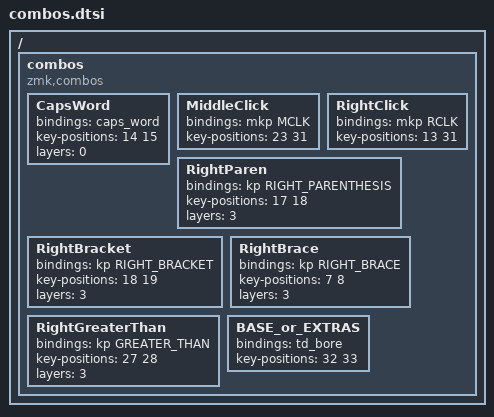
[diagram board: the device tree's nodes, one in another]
/ {
    combos {
        compatible = "zmk,combos";

        CapsWord {
            bindings = <&caps_word>;
            key-positions = <14 15>;
            layers = <0>;
        };

        MiddleClick {
            bindings = <&mkp MCLK>;
            key-positions = <23 31>;
        };

        RightClick {
            bindings = <&mkp RCLK>;
            key-positions = <13 31>;
        };

        RightParen {
            bindings = <&kp RIGHT_PARENTHESIS>;
            key-positions = <17 18>;
            layers = <3>;
        };

        RightBracket {
            bindings = <&kp RIGHT_BRACKET>;
            key-positions = <18 19>;
            layers = <3>;
        };

        RightBrace {
            bindings = <&kp RIGHT_BRACE>;
            key-positions = <7 8>;
            layers = <3>;
        };

        RightGreaterThan {
            bindings = <&kp GREATER_THAN>;
            key-positions = <27 28>;
            layers = <3>;
        };

        BASE_or_EXTRAS {
            bindings = <&td_bore>;
            key-positions = <32 33>;
        };

        // GameLayer {
        //     bindings = <&tog 4>;
        //     key-positions = <7 8>;
        // };

        // PhotoLayer {
        //     bindings = <&tog 5>;
        //     key-positions = <2 3>;
        // };
    };
};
